AUTOSAR XML (schema 314)
package /ComponentType
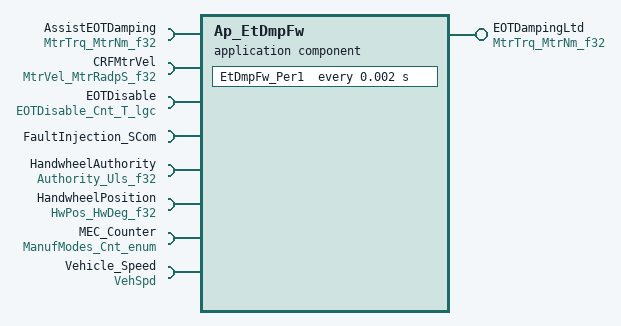
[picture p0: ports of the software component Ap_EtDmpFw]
  application software component type Ap_EtDmpFw
    provide port EOTDampingLtd: unqueued-sender-com-spec{data-element=MtrNm_f32, can-invalidate=false, init-value=D_ZERO_ULS_F32}, provided-interface=MtrTrq_MtrNm_f32
    8 x require port:
      AssistEOTDamping: unqueued-receiver-com-spec{data-element=MtrNm_f32, init-value=D_ZERO_ULS_F32}, required-interface=MtrTrq_MtrNm_f32
      CRFMtrVel: unqueued-receiver-com-spec{data-element=MtrRadpS_f32, init-value=D_ZERO_ULS_F32}, required-interface=MtrVel_MtrRadpS_f32
      EOTDisable: unqueued-receiver-com-spec{data-element=Cnt_lgc, init-value=D_FALSE_CNT_LGC}, required-interface=EOTDisable_Cnt_T_lgc
      FaultInjection_SCom: client-com-spec=FltInjection, required-interface=FaultInjection_SCom
      HandwheelAuthority: unqueued-receiver-com-spec{data-element=Uls_f32, init-value=D_ZERO_ULS_F32}, required-interface=Authority_Uls_f32
      HandwheelPosition: unqueued-receiver-com-spec{data-element=HwDeg_f32, init-value=D_ZERO_ULS_F32}, required-interface=HwPos_HwDeg_f32
      MEC_Counter: unqueued-receiver-com-spec{data-element=Cnt_enum, init-value=D_MANUFMODEINIT_CNT_ENUM}, required-interface=ManufModes_Cnt_enum
      Vehicle_Speed: unqueued-receiver-com-spec{data-element=Kph_f32, init-value=D_ZERO_ULS_F32}, required-interface=VehSpd
  internal behavior Ap_EtDmpFw_InternalBehavior: component=Ap_EtDmpFw
    timing event TMT_EtDmpFw_Per1: start-on-event=EtDmpFw_Per1, period=0.002
    port-api-options:
      enable-take-address=false, indirect-api=false, port=AssistEOTDamping
      enable-take-address=false, indirect-api=false, port=CRFMtrVel
      enable-take-address=false, indirect-api=false, port=EOTDampingLtd
      enable-take-address=false, indirect-api=false, port=EOTDisable
      enable-take-address=false, indirect-api=false, port=FaultInjection_SCom
      enable-take-address=false, indirect-api=false, port=HandwheelAuthority
      enable-take-address=false, indirect-api=false, port=HandwheelPosition
      enable-take-address=false, indirect-api=false, port=MEC_Counter
      enable-take-address=false, indirect-api=false, port=Vehicle_Speed
    runnable EtDmpFw_Per1
      7 x data read access:
        READ_AssistEOTDamping_MtrNm_f32: data-element=AssistEOTDamping.MtrNm_f32
        READ_CRFMtrVel_MtrRadpS_f32: data-element=CRFMtrVel.MtrRadpS_f32
        READ_EOTDisable_Cnt_lgc: data-element=EOTDisable.Cnt_lgc
        READ_HandwheelAuthority_Uls_f32: data-element=HandwheelAuthority.Uls_f32
        READ_HandwheelPosition_HwDeg_f32: data-element=HandwheelPosition.HwDeg_f32
        READ_MEC_Counter_Cnt_enum: data-element=MEC_Counter.Cnt_enum
        READ_Vehicle_Speed_Kph_f32: data-element=Vehicle_Speed.Kph_f32
      data write access WRITE_EOTDampingLtd_MtrNm_f32: data-element=EOTDampingLtd.MtrNm_f32
      sync call SC_FaultInjection_SCom_FltInjection: operation=FaultInjection_SCom.FltInjection, timeout=0
  swc implementation Ap_EtDmpFw_Implementation: behavior=Ap_EtDmpFw_InternalBehavior
    code-descriptors:
      code Code: type=SRC
